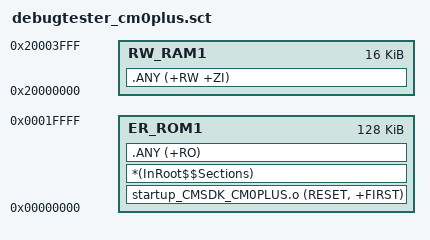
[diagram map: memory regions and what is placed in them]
;-----------------------------------------------------------------------------
; The confidential and proprietary information contained in this file may
; only be used by a person authorised under and to the extent permitted
; by a subsisting licensing agreement from Arm Limited or its affiliates.
;
;            (C) COPYRIGHT 2013 Arm Limited or its affiliates.
;                ALL RIGHTS RESERVED
;
; This entire notice must be reproduced on all copies of this file
; and copies of this file may only be made by a person if such person is
; permitted to do so under the terms of a subsisting license agreement
; from Arm Limited or its affiliates.
;
;      SVN Information
;
;      Checked In          : $Date: 2011-02-22 16:53:27 +0000 (Tue, 22 Feb 2011) $
;
;      Revision            : $Revision: 162307 $
;
;      Release Information : Cortex-M System Design Kit-r1p1-00rel0
;
;-----------------------------------------------------------------------------

; *************************************************************
; *** Scatter-Loading Description File generated by uVision ***
; *************************************************************

LR_ROM1 0x00000000 0x00020000  {    ; load region size_region
  ER_ROM1 0x00000000 0x00020000  {  ; load address = execution address
   startup_CMSDK_CM0PLUS.o (RESET, +FIRST)
   *(InRoot$$Sections)
   .ANY (+RO)
  }
  RW_RAM1 0x20000000 0x00004000  {  ; RW data
   .ANY (+RW +ZI)
  }
}

